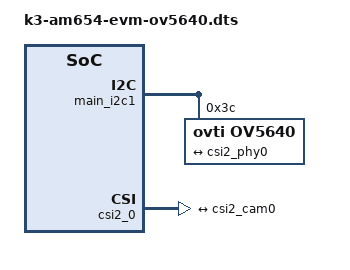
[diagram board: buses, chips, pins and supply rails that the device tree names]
// SPDX-License-Identifier: GPL-2.0
/*
 * Copyright (C) 2021 Texas Instruments Incorporated - http://www.ti.com/
 */

/dts-v1/;
/plugin/;

/ {
	fragment@101 {
		target-path = "/";

		__overlay__ {
			clk_ov5640_fixed: clock {
				compatible = "fixed-clock";
				#clock-cells = <0>;
				clock-frequency = <24000000>;
			};
		};
	};
};

&main_i2c1 {
	#address-cells = <1>;
	#size-cells = <0>;

	ov5640: camera@3c {
		compatible = "ovti,ov5640";
		reg = <0x3c>;

		clocks = <&clk_ov5640_fixed>;
		clock-names = "xclk";

		port {
			csi2_cam0: endpoint {
				remote-endpoint = <&csi2_phy0>;
				clock-lanes = <0>;
				data-lanes = <1 2>;
			};
		};
	};
};

&csi2_0 {
	csi2_phy0: endpoint {
		remote-endpoint = <&csi2_cam0>;
		clock-lanes = <0>;
		data-lanes = <1 2>;
	};
};
